# nrf54lilium_network register map
Vendor: Nordic Semiconductor; Series: nrf54; File version: 1
CPU: CM33 r0p4, little endian, MPU, no FPU, 3 interrupt priority bits, 30 interrupts
Registers are 32-bit, read-write, reset 0x0 unless marked. A register's access mark holds for its fields unless they carry their own. Offsets are from the block's base; [hi:lo] are bit positions; lines under a group give offsets from that group; {n}, {i} and the like mark numbered series; 'fields as' and 'values as' point back to an identical list.

## RADIO (part 1 of 3) — 2.4 GHz radio 2.4 GHz radio
Base 0x41008000
0x00 TASKS_TXEN wo — Enable RADIO in TX mode
  [0] TASKS_TXEN
    1=Trigger task
0x04 TASKS_RXEN wo — Enable RADIO in RX mode
  [0] TASKS_RXEN
    1=Trigger task
0x08 TASKS_START wo — Start RADIO
  [0] TASKS_START
    1=Trigger task
0x0C TASKS_STOP wo — Stop RADIO
  [0] TASKS_STOP
    1=Trigger task
0x10 TASKS_DISABLE wo — Disable RADIO
  [0] TASKS_DISABLE
    1=Trigger task
0x14 TASKS_RSSISTART wo — Start the RSSI and take one single sample of the receive signal strength
  [0] TASKS_RSSISTART
    1=Trigger task
0x18 TASKS_BCSTART wo — Start the bit counter
  [0] TASKS_BCSTART
    1=Trigger task
0x1C TASKS_BCSTOP wo — Stop the bit counter
  [0] TASKS_BCSTOP
    1=Trigger task
0x20 TASKS_EDSTART wo — Start the energy detect measurement used in IEEE 802.15.4 mode
  [0] TASKS_EDSTART
    1=Trigger task
0x24 TASKS_EDSTOP wo — Stop the energy detect measurement
  [0] TASKS_EDSTOP
    1=Trigger task
0x28 TASKS_CCASTART wo — Start the clear channel assessment used in IEEE 802.15.4 mode
  [0] TASKS_CCASTART
    1=Trigger task
0x2C TASKS_CCASTOP wo — Stop the clear channel assessment
  [0] TASKS_CCASTOP
    1=Trigger task
0x30 TASKS_DFESTART wo — Start DFE operation
  [0] TASKS_DFESTART
    1=Trigger task
0x34 TASKS_DFESTOP wo — Stop DFE operation
  [0] TASKS_DFESTOP
    1=Trigger task
0x38 TASKS_ACQINJ0DMASTART wo — Start DMA transaction
  [0] TASKS_ACQINJ0DMASTART
    1=Trigger task
0x3C TASKS_ACQINJ0DMASTOP wo — Stop ongoing DMA transaction
  [0] TASKS_ACQINJ0DMASTOP
    1=Trigger task
0x40 TASKS_ACQINJ1DMASTART wo — Start DMA transaction
  [0] TASKS_ACQINJ1DMASTART
    1=Trigger task
0x44 TASKS_ACQINJ1DMASTOP wo — Stop ongoing DMA transaction
  [0] TASKS_ACQINJ1DMASTOP
    1=Trigger task
0x48 TASKS_CNTPSTART wo — Start packet counter
  [0] TASKS_CNTPSTART
    1=Trigger task
0x4C TASKS_CNTPSTOP wo — Stop packet counter
  [0] TASKS_CNTPSTOP
    1=Trigger task
0x50 TASKS_CNTPCLEAR wo — Clear packet counter
  [0] TASKS_CNTPCLEAR
    1=Trigger task
0x54 TASKS_LOOPBACKEN wo — Enable RADIO in LOOPBACK mode
  [0] TASKS_LOOPBACKEN
    1=Trigger task
0x58 TASKS_CALSTART wo — Start calibration
  [0] TASKS_CALSTART
    1=Trigger task
0x5C TASKS_CALSTOP wo — Stop calibration
  [0] TASKS_CALSTOP
    1=Trigger task
0x60 TASKS_PATESTSTART wo — Start PA test
  [0] TASKS_PATESTSTART
    1=Trigger task
0x64 TASKS_PATESTSTOP wo — Stop PA test
  [0] TASKS_PATESTSTOP
    1=Trigger task
0x68 TASKS_CHNOINCR wo — Update RADIO channel based on the current channel and increment it according to chNoIncrStep
  [0] TASKS_CHNOINCR
    1=Trigger task
0x6C TASKS_DMASTART wo — Start RADIO DMA transaction
  [0] TASKS_DMASTART
    1=Trigger task
0x70 TASKS_DMASTOP wo — Stop ongoing RADIO DMA transaction
  [0] TASKS_DMASTOP
    1=Trigger task
0x74 TASKS_DFEDMASTART wo — Start DFE DMA transaction
  [0] TASKS_DFEDMASTART
    1=Trigger task
0x78 TASKS_DFEDMASTOP wo — Stop ongoing DFE DMA transaction
  [0] TASKS_DFEDMASTOP
    1=Trigger task
0x7C TASKS_RESERVED_31 wo — UNUSED_31
  [0] TASKS_RESERVED_31
    1=Trigger task
0x80 TASKS_GETNEXTDETECT wo — Pull the last item out of the detect FIFO
  [0] TASKS_GETNEXTDETECT
    1=Trigger task
0x84 TASKS_CLEARDETECTFIFO wo — Clear the detect FIFO
  [0] TASKS_CLEARDETECTFIFO
    1=Trigger task
0x88 TASKS_RESETDEMODCTRL wo — Sets all things back to original state in RxDemodCtrl
  [0] TASKS_RESETDEMODCTRL
    1=Trigger task
0x8C TASKS_DEMODCTRLSTARTTIMER wo — Start the built-in custom timer. When starting the timer, it always starts from 0
  [0] TASKS_DEMODCTRLSTARTTIMER
    1=Trigger task
0x90 TASKS_DEMODCTRLSTOPTIMER wo — Stop the built-in custom timer. When stopping the timer, it is always cleared afterwards
  [0] TASKS_DEMODCTRLSTOPTIMER
    1=Trigger task
{0x94+4i} TASKS_DEMODCTRLCONDEN{i} wo (i=0..2) — Enable condition {i}. After this task has been triggered, the condition will trigger exactly once
  [0] TASKS_DEMODCTRLCONDEN{i}
    1=Trigger task
0x100 EVENTS_READY — RADIO has ramped up and is ready to be started
  [0] EVENTS_READY
    0=NotGenerated (Event not generated); 1=Generated (Event generated)
0x104 EVENTS_TXREADY — RADIO has ramped up and is ready to be started TX path
  [0] EVENTS_TXREADY
    values as EVENTS_READY.EVENTS_READY
0x108 EVENTS_RXREADY — RADIO has ramped up and is ready to be started RX path
  [0] EVENTS_RXREADY
    values as EVENTS_READY.EVENTS_READY
0x10C EVENTS_ADDRESS — Address sent or received
  [0] EVENTS_ADDRESS
    values as EVENTS_READY.EVENTS_READY
0x110 EVENTS_FRAMESTART — IEEE 802.15.4 length field received
  [0] EVENTS_FRAMESTART
    values as EVENTS_READY.EVENTS_READY
0x114 EVENTS_PAYLOAD — Packet payload sent or received
  [0] EVENTS_PAYLOAD
    values as EVENTS_READY.EVENTS_READY
0x118 EVENTS_END — Packet sent or received
  [0] EVENTS_END
    values as EVENTS_READY.EVENTS_READY
0x11C EVENTS_PHYEND — The last bit is sent on air or last bit is received
  [0] EVENTS_PHYEND
    values as EVENTS_READY.EVENTS_READY
0x120 EVENTS_DISABLED — RADIO has been disabled
  [0] EVENTS_DISABLED
    values as EVENTS_READY.EVENTS_READY
0x124 EVENTS_DEVMATCH — A device address match occurred on the last received packet
  [0] EVENTS_DEVMATCH
    values as EVENTS_READY.EVENTS_READY
0x128 EVENTS_DEVMISS — No device address match occurred on the last received packet
  [0] EVENTS_DEVMISS
    values as EVENTS_READY.EVENTS_READY
0x12C EVENTS_CRCOK — Packet received with CRC ok
  [0] EVENTS_CRCOK
    values as EVENTS_READY.EVENTS_READY
0x130 EVENTS_CRCERROR — Packet received with CRC error
  [0] EVENTS_CRCERROR
    values as EVENTS_READY.EVENTS_READY
0x134 EVENTS_RESERVED_13 — UNUSED_13
  [0] EVENTS_RESERVED_13
    values as EVENTS_READY.EVENTS_READY
0x138 EVENTS_BCMATCH — Bit counter reached bit count value
  [0] EVENTS_BCMATCH
    values as EVENTS_READY.EVENTS_READY
0x13C EVENTS_EDEND — Sampling of energy detection complete. A new ED sample is ready for readout from the RADIO.EDSAMPLE register.
  [0] EVENTS_EDEND
    values as EVENTS_READY.EVENTS_READY
0x140 EVENTS_EDSTOPPED — The sampling of energy detection has stopped
  [0] EVENTS_EDSTOPPED
    values as EVENTS_READY.EVENTS_READY
0x144 EVENTS_CCAIDLE — Wireless medium in idle - clear to send
  [0] EVENTS_CCAIDLE
    values as EVENTS_READY.EVENTS_READY
0x148 EVENTS_CCABUSY — Wireless medium busy - do not send
  [0] EVENTS_CCABUSY
    values as EVENTS_READY.EVENTS_READY
0x14C EVENTS_CCASTOPPED — The CCA has stopped
  [0] EVENTS_CCASTOPPED
    values as EVENTS_READY.EVENTS_READY
0x150 EVENTS_RATEBOOST — Ble_LR CI field received, receive mode is changed from Ble_LR125Kbit to Ble_LR500Kbit
  [0] EVENTS_RATEBOOST
    values as EVENTS_READY.EVENTS_READY
0x154 EVENTS_MHRMATCH — MAC header match found
  [0] EVENTS_MHRMATCH
    values as EVENTS_READY.EVENTS_READY
0x158 EVENTS_SYNC — Initial sync detected
  [0] EVENTS_SYNC
    values as EVENTS_READY.EVENTS_READY
0x15C EVENTS_CTEPRESENT — CTEInfo byte is received
  [0] EVENTS_CTEPRESENT
    values as EVENTS_READY.EVENTS_READY
0x160 EVENTS_CTEWARNING — CTEInfo byte received, but contain illegal CTETime or CTEType.
  [0] EVENTS_CTEWARNING
    values as EVENTS_READY.EVENTS_READY
0x164 EVENTS_DFEEND — DFE operation has ended
  [0] EVENTS_DFEEND
    values as EVENTS_READY.EVENTS_READY
0x168 EVENTS_MODEWRITTEN — Generated on write access to MODE register
  [0] EVENTS_MODEWRITTEN
    values as EVENTS_READY.EVENTS_READY
0x16C EVENTS_MODEREADY — Generated immediately on write access to MODE register when MODEPROGENABLE==0, otherwise only manually triggered (SELECT_EVENTS_TRIGGERS=1)
  [0] EVENTS_MODEREADY
    values as EVENTS_READY.EVENTS_READY
0x170 EVENTS_CTEEND — CTE end
  [0] EVENTS_CTEEND
    values as EVENTS_READY.EVENTS_READY
0x174 EVENTS_LBREADY — RADIO is ready in loopback mode and is able to transmit and receive data
  [0] EVENTS_LBREADY
    values as EVENTS_READY.EVENTS_READY
0x178 EVENTS_CALDONE — RADIO calibration is done
  [0] EVENTS_CALDONE
    values as EVENTS_READY.EVENTS_READY
0x17C EVENTS_CHNOUPDATED — RADIO channel no. is updated
  [0] EVENTS_CHNOUPDATED
    values as EVENTS_READY.EVENTS_READY
0x180 EVENTS_DBCTIMEOUT — DBC timeout to be able to resync
  [0] EVENTS_DBCTIMEOUT
    values as EVENTS_READY.EVENTS_READY
0x184 EVENTS_TXTIMERMATCH — Tx timer match
  [0] EVENTS_TXTIMERMATCH
    values as EVENTS_READY.EVENTS_READY
0x188 EVENTS_RXTIMERMATCH — Rx timer match
  [0] EVENTS_RXTIMERMATCH
    values as EVENTS_READY.EVENTS_READY
0x18C EVENTS_RESERVED_35 — UNUSED_35
  [0] EVENTS_RESERVED_35
    values as EVENTS_READY.EVENTS_READY
0x190 EVENTS_RXDIGEN — RXDIGEN was set high from the HW timing engine
  [0] EVENTS_RXDIGEN
    values as EVENTS_READY.EVENTS_READY
0x194 EVENTS_RAWDETECT — The double correlator detected one peak
  [0] EVENTS_RAWDETECT
    values as EVENTS_READY.EVENTS_READY
0x198 EVENTS_DETECTFIFOFULL — The detect FIFO is full. This should not happen if the FIFO is sized well enough
  [0] EVENTS_DETECTFIFOFULL
    values as EVENTS_READY.EVENTS_READY
0x19C EVENTS_TIMERWRAPS — Event triggering when the timer wraps around. This is useful if one wants to count longer than the HW timer allows
  [0] EVENTS_TIMERWRAPS
    values as EVENTS_READY.EVENTS_READY
0x1A0 EVENTS_STROBETIMETRACKUPDATED — New information from the symbol time tracker. See STROBETIMESTATUS
  [0] EVENTS_STROBETIMETRACKUPDATED
    values as EVENTS_READY.EVENTS_READY
{0x1A4+4i} EVENTS_DEMODCTRLCONDTRIGGERED{i} (i=0..2) — Condition {i} triggered and actions done
  [0] EVENTS_DEMODCTRLCONDTRIGGERED{i}
    values as EVENTS_READY.EVENTS_READY
{0x100+4i} EVENTS_RESERVED_{i} (i=44..47) — UNUSED_{i}
  [0] EVENTS_RESERVED_{i}
    values as EVENTS_READY.EVENTS_READY
0x1C0 EVENTS_ACQINJ0DMAEND — ACQ DMA end
  [0] EVENTS_ACQINJ0DMAEND
    values as EVENTS_READY.EVENTS_READY
0x1C4 EVENTS_ACQINJ1DMAEND — INJ DMA end
  [0] EVENTS_ACQINJ1DMAEND
    values as EVENTS_READY.EVENTS_READY
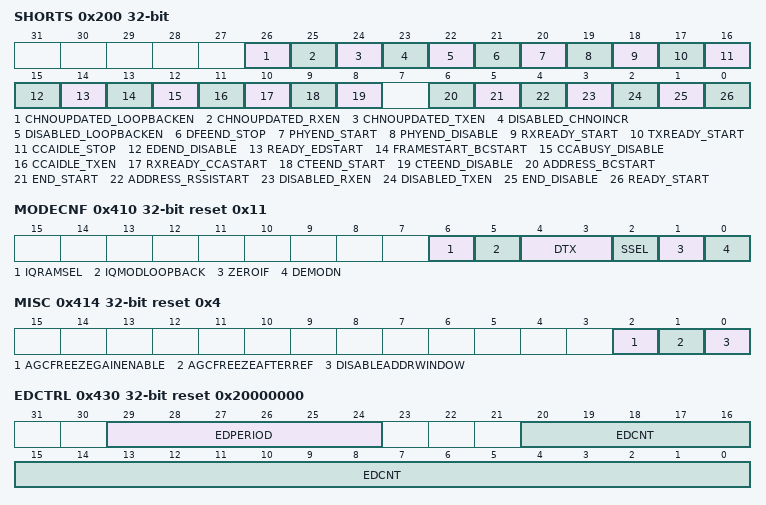
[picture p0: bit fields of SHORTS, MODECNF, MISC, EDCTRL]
0x200 SHORTS — Shortcuts between local events and tasks
  [all] fields
    0=Disabled (Disable shortcut); 1=Enabled (Enable shortcut)
  [26] CHNOUPDATED_LOOPBACKEN — Shortcut between event CHNOUPDATED and task LOOPBACKEN
  [25] CHNOUPDATED_RXEN — Shortcut between event CHNOUPDATED and task RXEN
  [24] CHNOUPDATED_TXEN — Shortcut between event CHNOUPDATED and task TXEN
  [23] DISABLED_CHNOINCR — Shortcut between event DISABLED and task CHNOINCR
  [22] DISABLED_LOOPBACKEN — Shortcut between event DISABLED and task LOOPBACKEN
  [21] DFEEND_STOP — Shortcut between event DFEEND and task STOP
  [20] PHYEND_START — Shortcut between event PHYEND and task START
  [19] PHYEND_DISABLE — Shortcut between event PHYEND and task DISABLE
  [18] RXREADY_START — Shortcut between event RXREADY and task START
  [17] TXREADY_START — Shortcut between event TXREADY and task START
  [16] CCAIDLE_STOP — Shortcut between event CCAIDLE and task STOP
  [15] EDEND_DISABLE — Shortcut between event EDEND and task DISABLE
  [14] READY_EDSTART — Shortcut between event READY and task EDSTART
  [13] FRAMESTART_BCSTART — Shortcut between event FRAMESTART and task BCSTART
  [12] CCABUSY_DISABLE — Shortcut between event CCABUSY and task DISABLE
  [11] CCAIDLE_TXEN — Shortcut between event CCAIDLE and task TXEN
  [10] RXREADY_CCASTART — Shortcut between event RXREADY and task CCASTART
  [9] CTEEND_START — Shortcut between event CTEEND and task START
  [8] CTEEND_DISABLE — Shortcut between event CTEEND and task DISABLE
  [6] ADDRESS_BCSTART — Shortcut between event ADDRESS and task BCSTART
  [5] END_START — Shortcut between event END and task START
  [4] ADDRESS_RSSISTART — Shortcut between event ADDRESS and task RSSISTART
  [3] DISABLED_RXEN — Shortcut between event DISABLED and task RXEN
  [2] DISABLED_TXEN — Shortcut between event DISABLED and task TXEN
  [1] END_DISABLE — Shortcut between event END and task DISABLE
  [0] READY_START — Shortcut between event READY and task START
0x300 INTEN00 — Enable or disable interrupt
0x304 INTEN01 — Enable or disable interrupt
  [17:0] INTEN01
0x308 INTENSET00 write-1-sets — Enable interrupt
0x30C INTENSET01 write-1-sets — Enable interrupt
  [17:0] INTENSET01
0x310 INTENCLR00 write-1-clears — Disable interrupt
0x314 INTENCLR01 write-1-clears — Disable interrupt
  [17:0] INTENCLR01
0x318 INTPEND00 ro — Pending interrupts
0x31C INTPEND01 ro — Pending interrupts
  [17:0] INTPEND01
0x320 INTEN10 — Enable or disable interrupt
0x324 INTEN11 — Enable or disable interrupt
  [17:0] INTEN11
0x328 INTENSET10 write-1-sets — Enable interrupt
0x32C INTENSET11 write-1-sets — Enable interrupt
  [17:0] INTENSET11
0x330 INTENCLR10 write-1-clears — Disable interrupt
0x334 INTENCLR11 write-1-clears — Disable interrupt
  [17:0] INTENCLR11
0x338 INTPEND10 ro — Pending interrupts
0x33C INTPEND11 ro — Pending interrupts
  [17:0] INTPEND11
0x400 MODE — Data rate and modulation
  [3:0] MODE — Radio data rate and modulation setting. The radio supports frequency-shift keying (FSK) modulation.
    0=Nrf_1Mbit (1 Mbps Nordic proprietary radio mode); 1=Nrf_2Mbit (2 Mbps Nordic proprietary radio mode); 2=Nrf_250Kbit (Deprecated enumerator - 250 kbps Nordic proprietary radio mode); 3=Ble_1Mbit (1 Mbps BLE); 4=Ble_2Mbit (2 Mbps BLE); 5=Ble_LR125Kbit (Long range 125 kbps TX, 125 kbps and 500 kbps RX); 6=Ble_LR500Kbit (Long range 500 kbps TX, 125 kbps and 500 kbps RX); 9=Nrf_4Mbit0_5 (4 Mbps Nordic proprietary radio mode (BT=0.5/h=0.5)); 10=Nrf_4Mbit0_25 (4 Mbps Nordic proprietary radio mode (BT=0.5/h=0.25)); 15=Ieee802154_250Kbit (IEEE 802.15.4-2006 250 kbps)
0x404 MODEINTERNAL — Internal mode setting, active only when MODEPROGENABLE==1
  [3:0] MODEINTERNAL — Radio data rate and modulation setting. Same definition as MODE.
0x408 MODEPROGENABLE — Switch that enables programmable modes
  [0] MODEPROGENABLE — Enable manual triggering of MODEREADY event and activate MODEINTERNAL register (ie. MODEINTERNAL overrides MODE register)
0x40C MODE_DEPENDENT_XPB_TEST_REGISTER
  [31:0] VAL — 32 bits, only for testing mode dependency
0x410 MODECNF reset 0x11 — Radio mode configuration register
  [6] IQRAMSEL — IQ RAM select
    0=off (IQ RAM select off); 1=on (IQ RAM select on)
  [5] IQMODLOOPBACK — Loopback from IQ modulator (TODO: is it a good place?)
    0=Off (Digital loopback off); 1=On (Digital loopback on)
  [4:3] DTX — Default TX value. Specifies what the RADIO will transmit when it is not started, i.e. between: RADIO.EVENTS_READY and RADIO.TASKS_START RADIO.EVENTS_END and RADIO.TASKS_START RADIO.EVENTS_END and RADIO.EVENTS_DISABLED)
    0=B1 (Transmit '1'); 1=B0 (Transmit '0'); 2=Center (Transmit center frequency When tuning the crystal for centre frequency, the RADIO must be set in DTX = Center mode to be able to achieve the expected accuracy. This is only a valid setting for Nrf_1Mbit, Nrf_2Mbit, Nrf_250kbit, Ble_1Mbit and Ble_2Mbit.)
  [2] SSEL — Sideband select
    0=Low (Low-side LO); 1=High-side LO
  [1] ZEROIF — Zero-IF mode
    0=Default mode (heterodyne); 1=Zero-IF mode
  [0] DEMODN — Demodulator mode override value
    0=Hyper demodulator mode; 1=Standard demodulator mode
0x414 MISC reset 0x4 — Misc configuration collection (to be renamed when more bits are defined)
  [2] AGCFREEZEGAINENABLE — Override AGC gain setting during CTE (from QOVERRIDE10)
    0=Adjust (AGC gain settings will keep adjusting during CTE); 1=Freeze (AGC gain settings will freeze (not keep adjusting) during CTE)
  [1] AGCFREEZEAFTERREF
    0=EntireCTE (Gain freeze will apply to whole CTE,); 1=AfterRefPeriod (Gain freeze will apply to only after reference period of CTE.)
  [0] DISABLEADDRWINDOW
    1=Disabled; 0=Enabled
0x420 STATE ro — Current radio state
  [3:0] STATE
    0=Disabled (RADIO is in the Disabled state); 1=RxRu (RADIO is in the RXRU state); 2=RxIdle (RADIO is in the RXIDLE state); 3=Rx (RADIO is in the RX state); 4=RxDisable (RADIO is in the RXDISABLED state); 9=TxRu (RADIO is in the TXRU state); 10=TxIdle (RADIO is in the TXIDLE state); 11=Tx (RADIO is in the TX state); 12=TxDisable (RADIO is in the TXDISABLED state)
0x430 EDCTRL reset 0x20000000 — IEEE 802.15.4 energy detect control
  [29:24] EDPERIOD — IEEE 802.15.4 energy detect/cca period, 4us resolution
  [20:0] EDCNT — IEEE 802.15.4 energy detect loop count
0x434 EDSAMPLE ro — IEEE 802.15.4 energy detect level
  [7:0] EDLVL
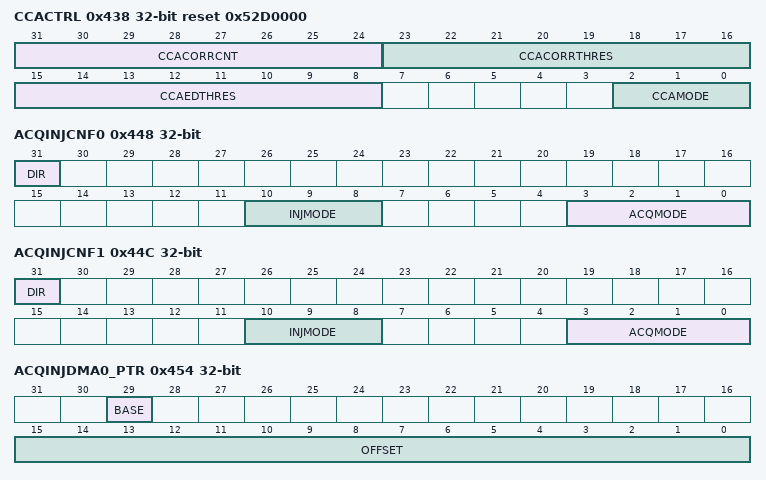
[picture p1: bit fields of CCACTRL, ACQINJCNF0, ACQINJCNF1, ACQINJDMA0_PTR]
0x438 CCACTRL reset 0x52D0000 — IEEE 802.15.4 clear channel assessment control
  [31:24] CCACORRCNT — Limit for occurances above CCACORRTHRES. When not equal to zero the corrolator based signal detect is enabled.
  [23:16] CCACORRTHRES — CCA correlator busy threshold. Only relevant to CarrierMode, CarrierAndEdMode, and CarrierOrEdMode.
  [15:8] CCAEDTHRES — CCA energy busy threshold. Used in all the CCA modes except CarrierMode.
  [2:0] CCAMODE — CCA mode of operation
    0=EdMode (Energy above threshold); 1=CarrierMode (Carrier seen); 2=CarrierAndEdMode (Energy above threshold AND carrier seen); 3=CarrierOrEdMode (Energy above threshold OR carrier seen); 4=EdModeTest1 (Energy above threshold test mode that will abort when first ED measurement over threshold is seen. No averaging.)
0x440 DATAWHITEIV reset 0x40 — Data whitening initial value
  [5:0] DATAWHITEIV
0x448 ACQINJCNF0 — Data acquisition capture mode
  [31] DIR — Data acquisition or injection
    0=ACQ (Peripheral to memory); 1=INJ (Memory to peripheral)
  [10:8] INJMODE — Data hijack mode (Do not select the same SRC for one than more DMAs. otherwise higher index takes over control.)
    0=FFSRC (Pick up IQ samples from RAM as FrontEnd input (hijack ADC output)); 1=BBSRC (Pick up IQ samples from RAM as Radio BaseBand input); 2=TXSRC (Pick up Tx bits from RAM (skipping packet assembler as modulator input); 6=ADPLLMODSRC (Pick up arbitrary wave from RAM to ADPLL)
  [3:0] ACQMODE — Data acquisition capture mode
    0=ADCIQ (Logging ADCI and ADCQ); 2=ADCIQANDAGCGAIN (Logging ADCI, ADCQ and AGC gain settings); 3=AGCGAINANDPKD (Logging AGC gain settings and peak detector outputs); 4=FEIQ (Logging FrontEnd sampleI and sampleQ); 5=BBIQ (Logging BaseBand I and Q); 6=BBSTDOUT (Logging BaseBand std demodulator outputs (original ones, not the delayed version)); 7=BBHYPOUT (Logging BaseBand hyp demodulator outputs); 8=BBSTDHYPMUXOUT (Logging muxed demodulator outputs and flags); 12=ADPLLTRACE (ADPLL tracing)
0x44C ACQINJCNF1 — Data acquisition capture mode
  fields as ACQINJCNF0
0x450 ACQINJDMA0_ENABLE — Enable or disable data acquisition
  [0] ACQINJDMA0_ENABLE
    0=Disabled (Data acquisition is disabled); 1=Enabled (Data acquisition is enabled)
0x454 ACQINJDMA0_PTR — ACQ DMA pointer
  [29] BASE, [15:0] OFFSET
0x458 ACQINJDMA0_MAXCNT — Maximum number of 32-bit words to transfer
  [13:0] ACQINJDMA0_MAXCNT
0x45C ACQINJDMA0_AMOUNT ro — Number of 32-bit words transferred in the last transaction
  [13:0] ACQINJDMA0_AMOUNT
0x460 ACQINJDMA1_ENABLE — Enable or disable data store
  [0] ACQINJDMA1_ENABLE
    0=Disabled (Data store is disabled); 1=Enabled (Data store is enabled)
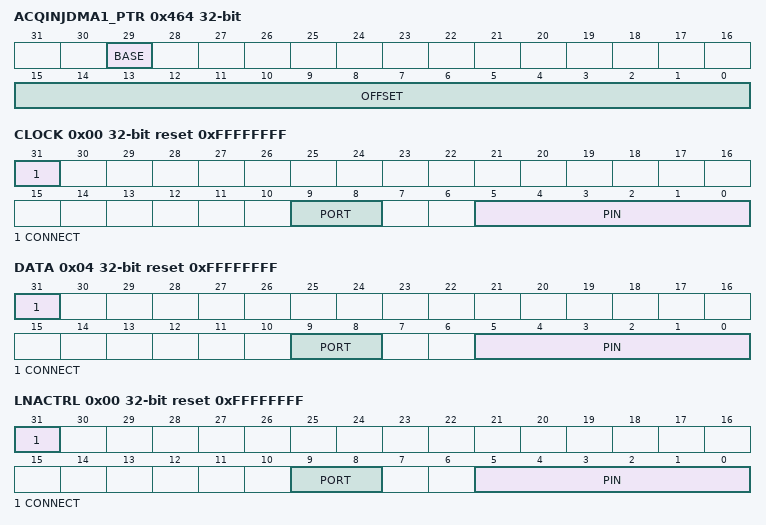
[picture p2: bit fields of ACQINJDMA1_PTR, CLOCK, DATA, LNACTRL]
0x464 ACQINJDMA1_PTR — ACQ DMA pointer
  [29] BASE, [15:0] OFFSET
0x468 ACQINJDMA1_MAXCNT — Maximum number of 32-bit words to transfer
  [13:0] MAXCNT
0x46C ACQINJDMA1_AMOUNT ro — Number of 32-bit words transferred in the last transaction
  [13:0] AMOUNT
0x488 DEBUGPSEL group — Unspecified
  0x00 CLOCK reset 0xFFFFFFFF — Pin select for RADIO clock (direct mode, base band debug. txCk and ckDataIn signals)
    [31] CONNECT — Connection
      1=Disconnected; 0=Connected
    [9:8] PORT — Port number
    [5:0] PIN — Pin number
  0x04 DATA reset 0xFFFFFFFF — Pin select for RADIO data (direct mode, base band debug. txRadioData and dataIn signals)
    fields as DEBUGPSEL.CLOCK
0x490 EXTPSEL group — Unspecified
  0x00 LNACTRL reset 0xFFFFFFFF — Pin select for external LNA control
    fields as DEBUGPSEL.CLOCK
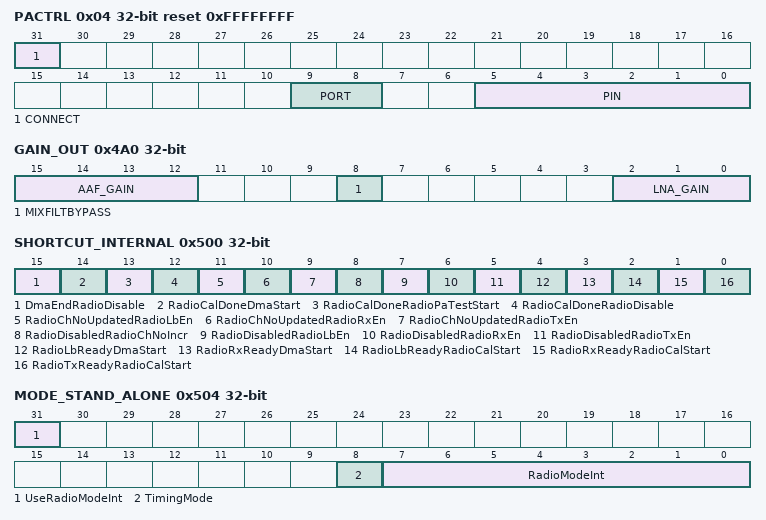
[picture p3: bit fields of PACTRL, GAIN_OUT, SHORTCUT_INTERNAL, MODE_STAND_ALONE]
  0x04 PACTRL reset 0xFFFFFFFF — Pin select for external PA control
    fields as DEBUGPSEL.CLOCK
0x4A0 GAIN_OUT ro — Gain readout (LNA_OUT_SPI for nrf52/53)
  [15:12] AAF_GAIN, [8] MIXFILTBYPASS, [2:0] LNA_GAIN
0x500 SHORTCUT_INTERNAL — TODO
  [15] DmaEndRadioDisable — Internal shortcut
  [14] RadioCalDoneDmaStart — Internal shortcut
  [13] RadioCalDoneRadioPaTestStart — Internal shortcut
  [12] RadioCalDoneRadioDisable — Internal shortcut
  [11] RadioChNoUpdatedRadioLbEn — Internal shortcut
  [10] RadioChNoUpdatedRadioRxEn — Internal shortcut
  [9] RadioChNoUpdatedRadioTxEn — Internal shortcut
  [8] RadioDisabledRadioChNoIncr — Internal shortcut
  [7] RadioDisabledRadioLbEn — Internal shortcut
  [6] RadioDisabledRadioRxEn — Internal shortcut
  [5] RadioDisabledRadioTxEn — Internal shortcut
  [4] RadioLbReadyDmaStart — Internal shortcut
  [3] RadioRxReadyDmaStart — Internal shortcut
  [2] RadioLbReadyRadioCalStart — Internal shortcut
  [1] RadioRxReadyRadioCalStart — Internal shortcut
  [0] RadioTxReadyRadioCalStart — Internal shortcut
0x504 MODE_STAND_ALONE — TODO
  [31] UseRadioModeInt — 0: use radioMode/radioModeUpdate from port (controlled from top), 1: use radioMode/radioModeUpdate from registers in this IP
  [8] TimingMode — 0: Default ramp-up time, compatible with 180nm radio. 1: Fast ramp-up.
  [7:0] RadioModeInt — Internal radio mode consists of sSel, zeroIf, deModN and mode[3:0]
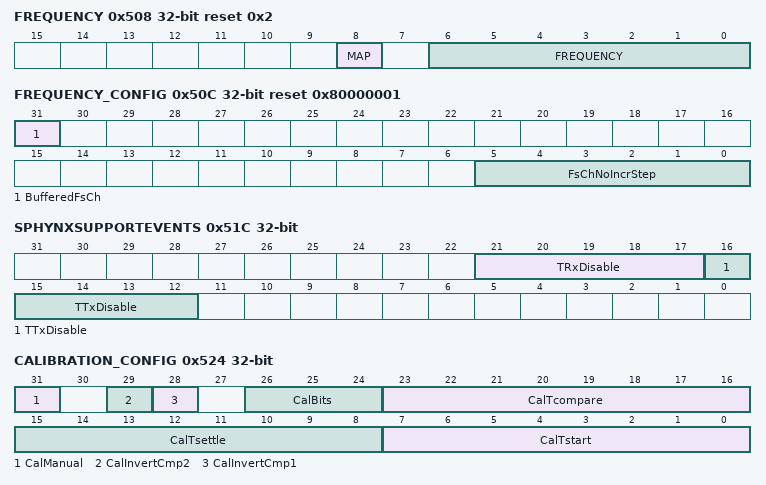
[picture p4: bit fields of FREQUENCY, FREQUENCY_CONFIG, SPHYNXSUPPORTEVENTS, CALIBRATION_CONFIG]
0x508 FREQUENCY ro reset 0x2
  [8] MAP — Channel map selection. 0: Channel map between 2400 MHZ .. 2500 MHz, Frequency = 2400 + FREQUENCY (MHz). 1: Channel map between 2400 MHZ .. 2500 MHz, Frequency = 2360 + FREQUENCY (MHz).
  [6:0] FREQUENCY — Radio channel frequency. Frequency = 2400 + FREQUENCY (MHz).
0x50C FREQUENCY_CONFIG reset 0x80000001 — TODO
  [31] BufferedFsCh — Set to high to buffer FREQUENCY register so that sub-modules in the MMI will only update next frequency config at TX_EN, RX_EN and LB_EN. Set to low if special test is needed for FS test.
  [5:0] FsChNoIncrStep — Radio channel incremental step unit.
0x510 TXPOWER — Output power
  [7:0] TXPOWER — RADIO output power
    11=Pos10dBm_2 (+10 dBm); {v}=Pos{v}dBm (+{v} dBm) (v=1..10); 0=0dBm; 255=Neg1dBm (-1 dBm); 254=Neg2dBm (-2 dBm); 252=Neg4dBm (-4 dBm); 248=Neg8dBm (-8 dBm); 244=Neg12dBm (-12 dBm); 240=Neg16dBm (-16 dBm); 236=Neg20dBm (-20 dBm); 226=Neg30dBm (-30 dBm); 216=Neg40dBm (-40 dBm); 186=Neg70dBm (-70 dBm)
0x514 TIFS — Interframe spacing in us
  [9:0] TIFS — Interframe spacing in us. Interframe space is the time interval between two consecutive packets. It is defined as the time, in microseconds, from the end of the last bit of the previous packet to the start of the first bit of the subsequent packet.
0x51C SPHYNXSUPPORTEVENTS — TODO
  [21:17] TRxDisable — Transition time from TXDISABLE state to DISABLED state. (unit: 1us)
  [16:12] TTxDisable — Transition time from RXDISABLE state to DISABLED state. (unit: 1us)
0x520 CALIBRATION_TARGET — TODO
  [2:0] CalTarget — Calibration target selection for calibration engine. 0: DC_CAL, 1: RC_CAL
0x524 CALIBRATION_CONFIG — TODO
  [31] CalManual — 0: use hard-coded calibration timing, 1: use manual calibration timing above
  [29] CalInvertCmp2 — 1: invert calCmp2 before it goes into calibration engine #2
  [28] CalInvertCmp1 — 1: invert calCmp1 before it goes into calibration engine #1
  [26:24] CalBits — Number of valid bits to be calibrated
  [23:16] CalTcompare — Compare wait time
  [15:8] CalTsettle — Settle wait time
  [7:0] CalTstart — Startup wait time
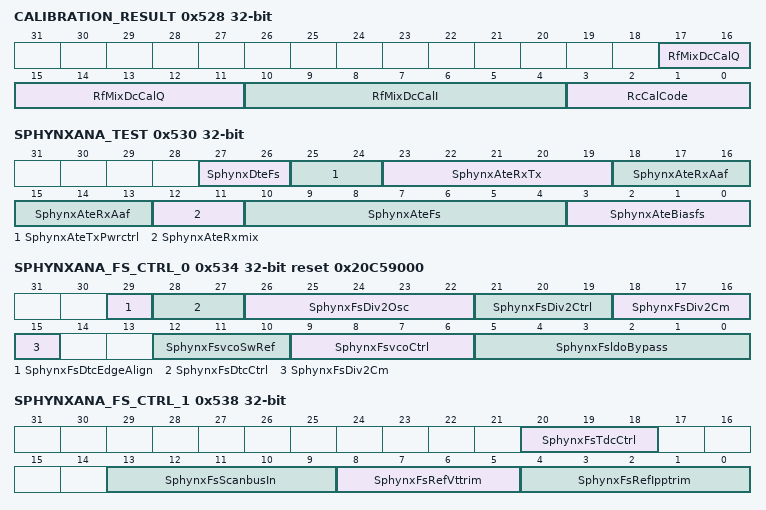
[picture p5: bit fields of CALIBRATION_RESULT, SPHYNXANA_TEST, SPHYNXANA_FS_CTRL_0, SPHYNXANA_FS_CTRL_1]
0x528 CALIBRATION_RESULT ro — TODO
  [17:11] RfMixDcCalQ — Calibration result from DC offset calibration on channel Q
  [10:4] RfMixDcCalI — Calibration result from DC offset calibration on channel I
  [3:0] RcCalCode — Calibration result from RC calibration
0x530 SPHYNXANA_TEST — TODO
  [27:26] SphynxDteFs — Digital test enable for digital logic in analog macro
  [25:24] SphynxAteTxPwrctrl — Analog test enable for TX PWRCTRL
  [23:19] SphynxAteRxTx — Analog test enable for RX TX
  [18:13] SphynxAteRxAaf — Analog test enable for RX AAF
  [12:11] SphynxAteRxmix — Analog test enable for RX MIX
  [10:4] SphynxAteFs — Analog test enable for FS
  [3:0] SphynxAteBiasfs — Analog test enable for BIAS_FS
0x534 SPHYNXANA_FS_CTRL_0 reset 0x20C59000 — TODO
  [29] SphynxFsDtcEdgeAlign — Resync at flip flop inside DTC
  [28:27] SphynxFsDtcCtrl — 0: controls bleed current from supply, 1: bypasses DTC to send XO out directly
  [26:22] SphynxFsDiv2Osc — Change back bias of NMOS in ROSC inside DIV2
  [21:19] SphynxFsDiv2Ctrl — Spare, not used
  [18:15] SphynxFsDiv2Cm — Set common mode for DIV2
  [12:10] SphynxFsvcoSwRef — FS swing calibration
  [9:6] SphynxFsvcoCtrl — Spare, not used
  [5:0] SphynxFsldoBypass — Bypass FS LDOs
0x538 SPHYNXANA_FS_CTRL_1 — TODO
  [20:18] SphynxFsTdcCtrl — Spare, not used
  [13:9] SphynxFsScanbusIn — DFT control/scan-in to AdPll. [4]: arstScan, [3]: scanTest, [2]: scanCk, [1]: scanEn, [0]: scanIn
  [8:5] SphynxFsRefVttrim — For voltage tuning of reference
  [4:0] SphynxFsRefIpptrim — For current calibration
0x53C SPHYNXANA_FS_CTRL_2 — TODO
  [4:0] SphynxSwatTrim — SWAT_TRIM_0V8[2:0] for SWAT_VREF trimming (default is 3b'000) and SWAT_TRIM_0V8[4:3] (default is 2b'00) for IBPSR trimming
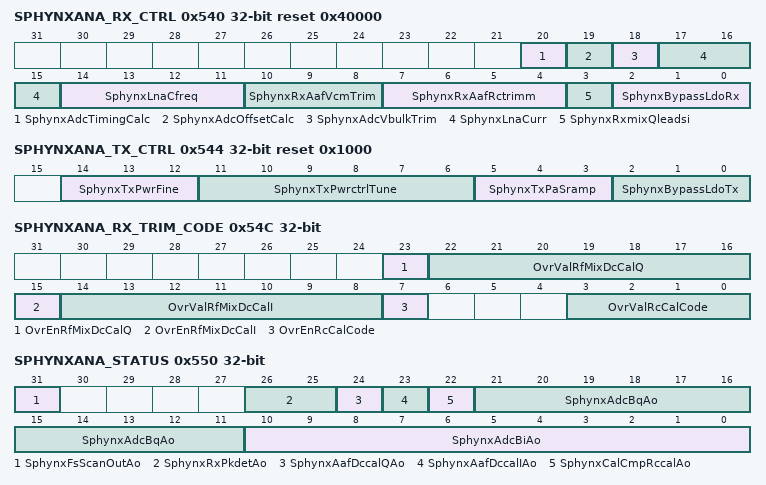
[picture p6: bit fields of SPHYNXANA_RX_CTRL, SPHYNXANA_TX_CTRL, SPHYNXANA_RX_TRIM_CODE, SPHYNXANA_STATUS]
0x540 SPHYNXANA_RX_CTRL reset 0x40000 — TODO
  [20] SphynxAdcTimingCalc — TODO
  [19] SphynxAdcOffsetCalc — TODO
  [18] SphynxAdcVbulkTrim — TODO
  [17:15] SphynxLnaCurr — TODO
  [14:11] SphynxLnaCfreq — TODO
  [10:8] SphynxRxAafVcmTrim — TODO
  [7:4] SphynxRxAafRctrimm — RC trim values for RX_AAF generated by RC_CAL
  [3] SphynxRxmixQleadsi — 1: output from MIX_AMP is Q leading I, 0 output from MIX_AMP is I leading Q.
  [2:0] SphynxBypassLdoRx — Bypass Rx LDOs.
0x544 SPHYNXANA_TX_CTRL reset 0x1000 — TODO
  [14:12] SphynxTxPwrFine — Radio Tx output power fine tune.
  [11:6] SphynxTxPwrctrlTune — TODO
  [5:3] SphynxTxPaSramp — TX PA ramp up/down control.
  [2:0] SphynxBypassLdoTx — Bypass Tx LDOs.
0x548 SPHYNXANA_MODE_DEPENDENT — TODO
  [0] SphynxRxAafFreq — Select Rx IF frequency. 0: 1Mbps, 1: 2Mbps(4Mbps)
0x54C SPHYNXANA_RX_TRIM_CODE — TODO
  [23] OvrEnRfMixDcCalQ — For RXMIX_DCCAL_Q_0V8, 0: controlled by CalibrationEngine, 1: overridden by register
  [22:16] OvrValRfMixDcCalQ — Override values on RXMIX_DCCAL_Q_0V8
  [15] OvrEnRfMixDcCalI — For RXMIX_DCCAL_I_0V8, 0: controlled by CalibrationEngine, 1: overridden by register
  [14:8] OvrValRfMixDcCalI — Override values on RXMIX_DCCAL_I_0V8
  [7] OvrEnRcCalCode — For RCCAL_CODE_0V8, 0: controlled by CalibrationEngine, 1: overridden by register
  [3:0] OvrValRcCalCode — Override values on RCCAL_CODE_0V8
0x550 SPHYNXANA_STATUS ro — TODO
  [31] SphynxFsScanOutAo — DFT Scan-out from AdPll
  [26:25] SphynxRxPkdetAo — Raw peak detector output from RX_PKDET
  [24] SphynxAafDccalQAo — Raw comparator output of DC calibration from RX_AAF Q channel
  [23] SphynxAafDccalIAo — Raw comparator output of DC calibration from RX_AAF I channel
  [22] SphynxCalCmpRccalAo — Raw comparator output of RC calibration from RC_CAL
  [21:11] SphynxAdcBqAo — Raw ADC Q channel output from RX_SAR2
  [10:0] SphynxAdcBiAo — Raw ADC I channel output from RX_SAR2
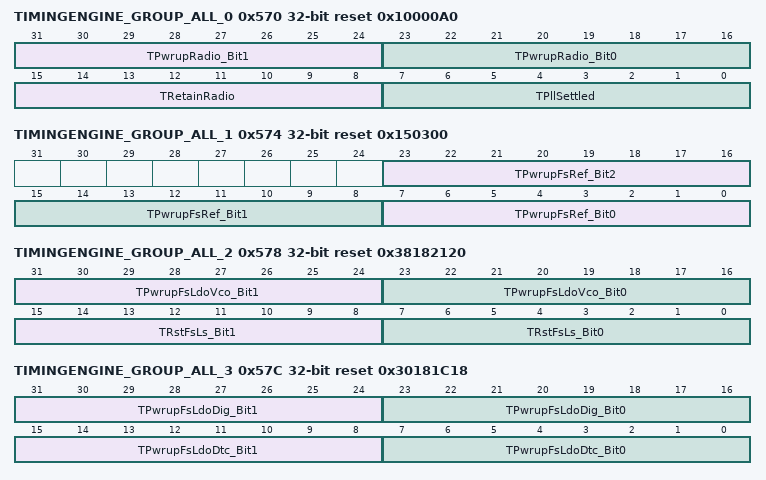
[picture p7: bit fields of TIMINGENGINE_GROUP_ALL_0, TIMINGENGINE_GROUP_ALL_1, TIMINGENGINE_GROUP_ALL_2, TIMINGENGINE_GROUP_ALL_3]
0x570 TIMINGENGINE_GROUP_ALL_0 reset 0x10000A0 — TODO
  [31:24] TPwrupRadio_Bit1 — (unit: 0.25us) Timing control of pwrupRadio[1]
  [23:16] TPwrupRadio_Bit0 — (unit: 0.25us) Timing control of pwrupRadio[0]
  [15:8] TRetainRadio — (unit: 0.25us) Timing control of retainRadio
  [7:0] TPllSettled — (unit: 0.25us) Timing control of pllSettled
0x574 TIMINGENGINE_GROUP_ALL_1 reset 0x150300 — TODO
  [23:16] TPwrupFsRef_Bit2 — (unit: 0.25us) Timing control of PwrupFsRef[2]
  [15:8] TPwrupFsRef_Bit1 — (unit: 0.25us) Timing control of PwrupFsRef[1]
  [7:0] TPwrupFsRef_Bit0 — (unit: 0.25us) Timing control of PwrupFsRef[0]
0x578 TIMINGENGINE_GROUP_ALL_2 reset 0x38182120 — TODO
  [31:24] TPwrupFsLdoVco_Bit1 — (unit: 0.25us) Timing control of PwrupFsLdoVco[1]
  [23:16] TPwrupFsLdoVco_Bit0 — (unit: 0.25us) Timing control of PwrupFsLdoVco[0]
  [15:8] TRstFsLs_Bit1 — (unit: 0.25us) Timing control of RstFsLs[1]
  [7:0] TRstFsLs_Bit0 — (unit: 0.25us) Timing control of RstFsLs[0]
0x57C TIMINGENGINE_GROUP_ALL_3 reset 0x30181C18 — TODO
  [31:24] TPwrupFsLdoDig_Bit1 — (unit: 0.25us) Timing control of PwrupFsLdoDig[1]
  [23:16] TPwrupFsLdoDig_Bit0 — (unit: 0.25us) Timing control of PwrupFsLdoDig[0]
  [15:8] TPwrupFsLdoDtc_Bit1 — (unit: 0.25us) Timing control of PwrupFsLdoDtc[1]
  [7:0] TPwrupFsLdoDtc_Bit0 — (unit: 0.25us) Timing control of PwrupFsLdoDtc[0]
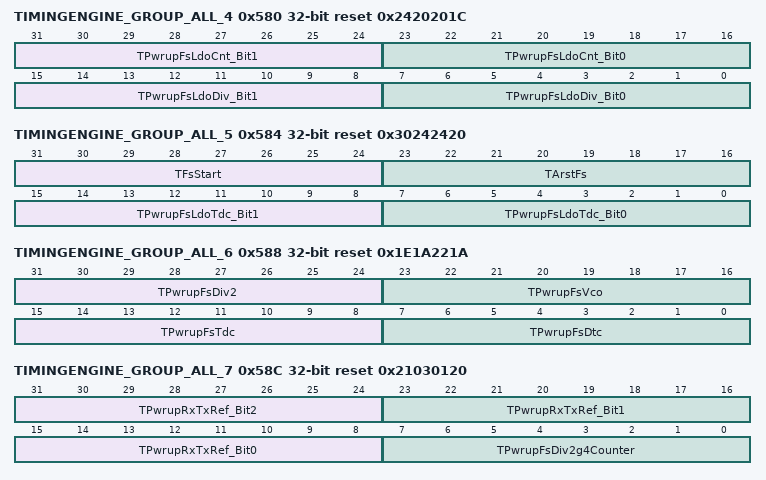
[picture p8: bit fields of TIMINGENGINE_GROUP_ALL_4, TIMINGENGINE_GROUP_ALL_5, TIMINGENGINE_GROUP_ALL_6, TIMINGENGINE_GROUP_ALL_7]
0x580 TIMINGENGINE_GROUP_ALL_4 reset 0x2420201C — TODO
  [31:24] TPwrupFsLdoCnt_Bit1 — (unit: 0.25us) Timing control of PwrupFsLdoCnt[1]
  [23:16] TPwrupFsLdoCnt_Bit0 — (unit: 0.25us) Timing control of PwrupFsLdoCnt[0]
  [15:8] TPwrupFsLdoDiv_Bit1 — (unit: 0.25us) Timing control of PwrupFsLdoDiv[1]
  [7:0] TPwrupFsLdoDiv_Bit0 — (unit: 0.25us) Timing control of PwrupFsLdoDiv[0]
0x584 TIMINGENGINE_GROUP_ALL_5 reset 0x30242420 — TODO
  [31:24] TFsStart — (unit: 0.25us) Timing control of FsStart
  [23:16] TArstFs — (unit: 0.25us) Timing control of ArstFs
  [15:8] TPwrupFsLdoTdc_Bit1 — (unit: 0.25us) Timing control of PwrupFsLdoTdc[1]
  [7:0] TPwrupFsLdoTdc_Bit0 — (unit: 0.25us) Timing control of PwrupFsLdoTdc[0]
0x588 TIMINGENGINE_GROUP_ALL_6 reset 0x1E1A221A — TODO
  [31:24] TPwrupFsDiv2 — (unit: 0.25us) Timing control of PwrupFsDiv2
  [23:16] TPwrupFsVco — (unit: 0.25us) Timing control of PwrupFsVco
  [15:8] TPwrupFsTdc — (unit: 0.25us) Timing control of PwrupFsTdc
  [7:0] TPwrupFsDtc — (unit: 0.25us) Timing control of PwrupFsDtc
0x58C TIMINGENGINE_GROUP_ALL_7 reset 0x21030120 — TODO
  [31:24] TPwrupRxTxRef_Bit2 — (unit: 0.25us) Timing control of PwrupRxTxRef[2]
  [23:16] TPwrupRxTxRef_Bit1 — (unit: 0.25us) Timing control of PwrupRxTxRef[1]
  [15:8] TPwrupRxTxRef_Bit0 — (unit: 0.25us) Timing control of PwrupRxTxRef[0]
  [7:0] TPwrupFsDiv2g4Counter — (unit: 0.25us) Timing control of PwrupFsDiv2g4Counter
0x590 TIMINGENGINE_GROUP_ALL_8 reset 0x28 — TODO
  [7:0] TRstFsLs_Bit2 — (unit: 0.25us) Timing control of RstFsLs[2]
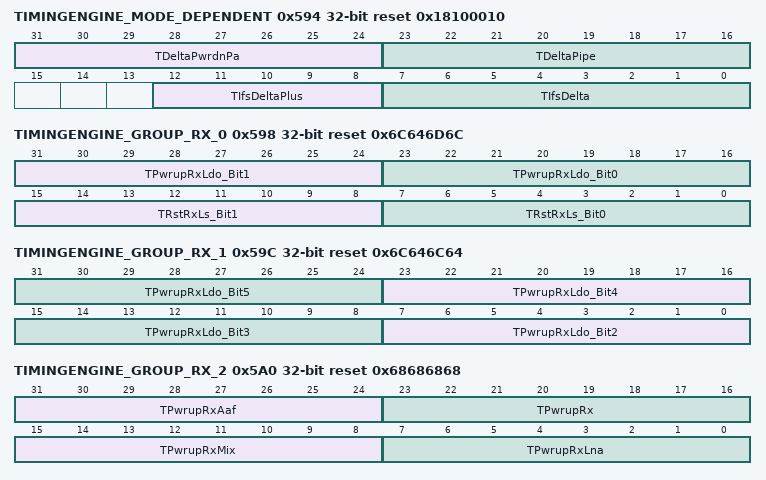
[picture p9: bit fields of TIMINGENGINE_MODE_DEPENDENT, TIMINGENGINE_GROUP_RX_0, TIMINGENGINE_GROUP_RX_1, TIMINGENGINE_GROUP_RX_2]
0x594 TIMINGENGINE_MODE_DEPENDENT reset 0x18100010 — TODO
  [31:24] TDeltaPwrdnPa — (unit: 0.25us) Timing control of DeltaPwrdnPa
  [23:16] TDeltaPipe — (unit: 0.25us) Timing control of DeltaPipe
  [12:8] TIfsDeltaPlus — (unit: 0.25us) Timing control of IfsDeltaPlus
  [7:0] TIfsDelta — (unit: 0.25us) Timing control of IfsDelta
0x598 TIMINGENGINE_GROUP_RX_0 reset 0x6C646D6C — TODO
  [31:24] TPwrupRxLdo_Bit1 — (unit: 0.25us) Timing control of PwrupRxLdo[1]
  [23:16] TPwrupRxLdo_Bit0 — (unit: 0.25us) Timing control of PwrupRxLdo[0]
  [15:8] TRstRxLs_Bit1 — (unit: 0.25us) Timing control of RstRxLs[1]
  [7:0] TRstRxLs_Bit0 — (unit: 0.25us) Timing control of RstRxLs[0]
0x59C TIMINGENGINE_GROUP_RX_1 reset 0x6C646C64 — TODO
  [8n-9:8n-16] TPwrupRxLdo_Bit{n} (n=2..5) — (unit: 0.25us) Timing control of PwrupRxLdo[{n}]
0x5A0 TIMINGENGINE_GROUP_RX_2 reset 0x68686868 — TODO
  [31:24] TPwrupRxAaf — (unit: 0.25us) Timing control of PwrupRxAaf
  [23:16] TPwrupRx — (unit: 0.25us) Timing control of PwrupRx
  [15:8] TPwrupRxMix — (unit: 0.25us) Timing control of PwrupRxMix
  [7:0] TPwrupRxLna — (unit: 0.25us) Timing control of PwrupRxLna
